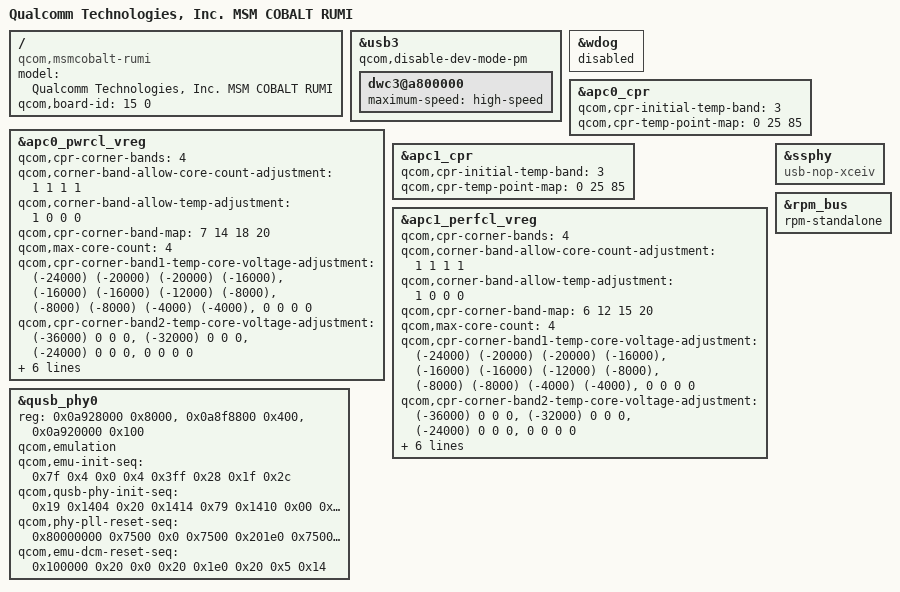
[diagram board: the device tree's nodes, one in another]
/* Copyright (c) 2015-2016, The Linux Foundation. All rights reserved.
 *
 * This program is free software; you can redistribute it and/or modify
 * it under the terms of the GNU General Public License version 2 and
 * only version 2 as published by the Free Software Foundation.
 *
 * This program is distributed in the hope that it will be useful,
 * but WITHOUT ANY WARRANTY; without even the implied warranty of
 * MERCHANTABILITY or FITNESS FOR A PARTICULAR PURPOSE.  See the
 * GNU General Public License for more details.
 */


/dts-v1/;
/memreserve/ 0x90000000 0x00000100;

#include "msmcobalt.dtsi"
#include "msmcobalt-rumi.dtsi"

/ {
	model = "Qualcomm Technologies, Inc. MSM COBALT RUMI";
	compatible = "qcom,msmcobalt-rumi", "qcom,msmcobalt", "qcom,rumi";
	qcom,board-id = <15 0>;
};

&usb3 {
	qcom,disable-dev-mode-pm;
	dwc3@a800000 {
		maximum-speed = "high-speed";
	};
};

&wdog {
	status = "disabled";
};

&apc0_cpr {
	qcom,cpr-initial-temp-band = <3>;
	qcom,cpr-temp-point-map = <0 25 85>;
};

&apc0_pwrcl_vreg {
	qcom,cpr-corner-bands = <4>;
	qcom,corner-band-allow-core-count-adjustment = <1 1 1 1>;
	qcom,corner-band-allow-temp-adjustment = <1 0 0 0>;
	qcom,cpr-corner-band-map = <7 14 18 20>;
	qcom,max-core-count = <4>;
	qcom,cpr-corner-band1-temp-core-voltage-adjustment =
		<(-24000) (-20000) (-20000) (-16000)>,
		<(-16000) (-16000) (-12000) (-8000)>,
		<(-8000)  (-8000)  (-4000)  (-4000)>,
		<0     0     0     0>;
	qcom,cpr-corner-band2-temp-core-voltage-adjustment =
		<(-36000) 0 0 0>,
		<(-32000) 0 0 0>,
		<(-24000) 0 0 0>,
		<    0 0 0 0>;
	qcom,cpr-corner-band3-temp-core-voltage-adjustment =
		<(-40000) 0 0 0>,
		<(-36000) 0 0 0>,
		<(-32000) 0 0 0>,
		<    0 0 0 0>;
	qcom,cpr-corner-band4-temp-core-voltage-adjustment =
		<(-44000) 0 0 0>,
		<(-32000) 0 0 0>,
		<(-24000) 0 0 0>,
		<    0 0 0 0>;
};

&apc1_cpr {
	qcom,cpr-initial-temp-band = <3>;
	qcom,cpr-temp-point-map = <0 25 85>;
};

&apc1_perfcl_vreg {
	qcom,cpr-corner-bands = <4>;
	qcom,corner-band-allow-core-count-adjustment = <1 1 1 1>;
	qcom,corner-band-allow-temp-adjustment = <1 0 0 0>;
	qcom,cpr-corner-band-map = <6 12 15 20>;
	qcom,max-core-count = <4>;
	qcom,cpr-corner-band1-temp-core-voltage-adjustment =
		<(-24000) (-20000) (-20000) (-16000)>,
		<(-16000) (-16000) (-12000) (-8000)>,
		<(-8000)  (-8000)  (-4000)  (-4000)>,
		<0     0     0     0>;
	qcom,cpr-corner-band2-temp-core-voltage-adjustment =
		<(-36000) 0 0 0>,
		<(-32000) 0 0 0>,
		<(-24000) 0 0 0>,
		<    0 0 0 0>;
	qcom,cpr-corner-band3-temp-core-voltage-adjustment =
		<(-40000) 0 0 0>,
		<(-36000) 0 0 0>,
		<(-32000) 0 0 0>,
		<    0 0 0 0>;
	qcom,cpr-corner-band4-temp-core-voltage-adjustment =
		<(-44000) 0 0 0>,
		<(-32000) 0 0 0>,
		<(-24000) 0 0 0>,
		<    0 0 0 0>;
};

&qusb_phy0 {
	reg = <0x0a928000 0x8000>,
	    <0x0a8f8800 0x400>,
	    <0x0a920000 0x100>;
	reg-names = "qusb_phy_base",
		"qscratch_base",
		"emu_phy_base";
	qcom,emulation;
	qcom,emu-init-seq = <0x7f 0x4
			0x0 0x4
			0x3ff 0x28
			0x1f 0x2c>;
	qcom,qusb-phy-init-seq = <0x19 0x1404
				0x20 0x1414
				0x79 0x1410
				0x00 0x1418
				0x99 0x1404
				0x04 0x1408
				0xd9 0x1404>;
	qcom,phy-pll-reset-seq = <0x80000000 0x7500
				0x0 0x7500
				0x201e0 0x7500
				0x0 0x7500>;
	qcom,emu-dcm-reset-seq = <0x100000 0x20
				0x0 0x20
				0x1e0 0x20
				0x5 0x14>;
};

&ssphy {
	compatible =  "usb-nop-xceiv";
};

&rpm_bus {
	rpm-standalone;
};
